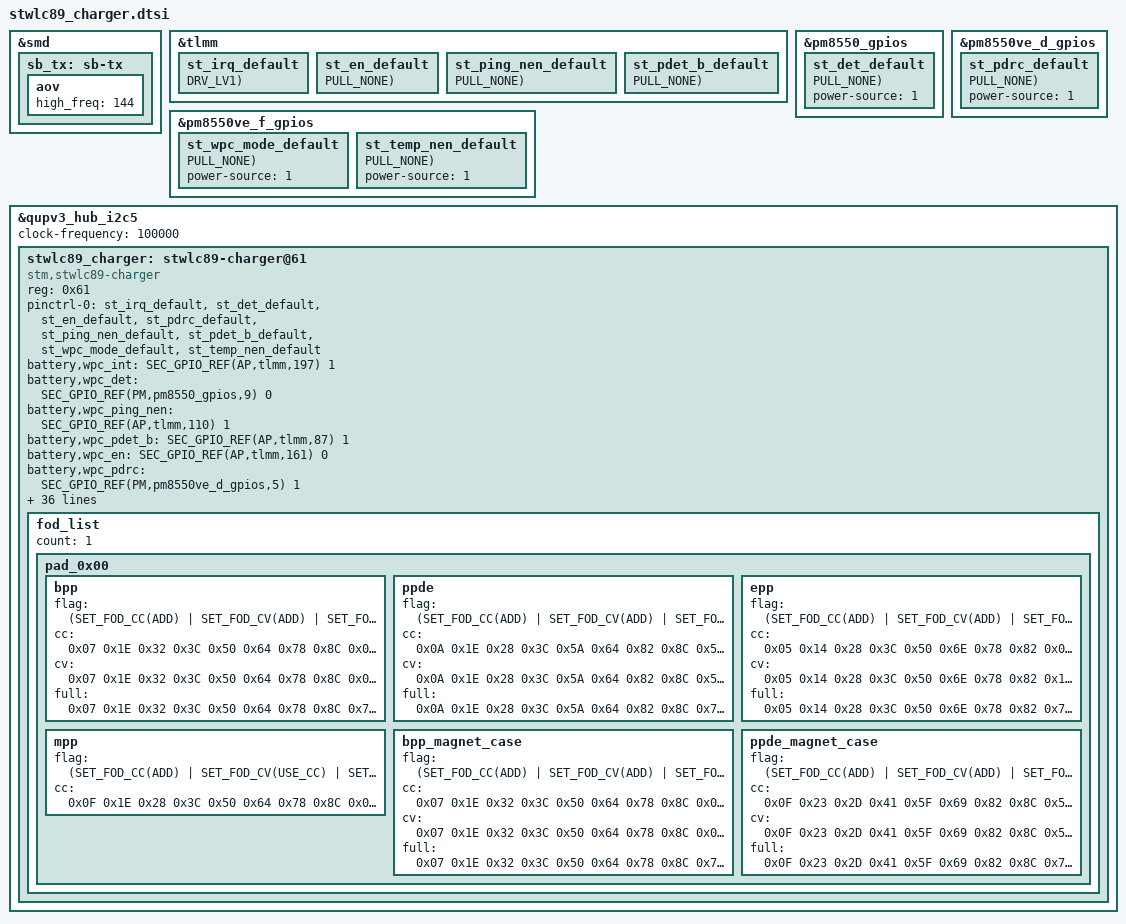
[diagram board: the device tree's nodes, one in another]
#include <dt-bindings/battery/sec-battery.h>

&smd {
	sb_tx: sb-tx {
	       aov {
		       high_freq = <144>;
	       };
       };
};

&tlmm {
	st_irq_default: st_irq_default {
		GPIO_CONFIG_PUD_DRV(AP,tlmm,197, FUNC_INPUT_WAKEUP, PULL_NONE, DRV_LV1);
	};
};

&pm8550_gpios {
	st_det_default: st_det_default {
		GPIO_CONFIG_PUD(PM,pm8550_gpios,9, FUNC_INPUT_WAKEUP, PULL_NONE);
	};
};

&tlmm {
	st_en_default: st_en_default {
		GPIO_CONFIG_PUD(AP,tlmm,161, FUNC_OUTPUT_LOW, PULL_NONE);
	};
};

#if 1
&pm8550ve_d_gpios {
	st_pdrc_default: st_pdrc_default {
		GPIO_CONFIG_PUD(PM,pm8550ve_d_gpios,5, FUNC_INPUT_WAKEUP, PULL_NONE);
	};
};
#endif

#if 1
&tlmm {
	st_ping_nen_default: st_ping_nen_default {
		GPIO_CONFIG_PUD(AP,tlmm,110, FUNC_OUTPUT_HIGH, PULL_NONE);
	};
};
#endif

#if 1
&tlmm {
	st_pdet_b_default: st_pdet_b_default {
		GPIO_CONFIG_PUD(AP,tlmm,87, FUNC_INPUT_WAKEUP, PULL_NONE);
	};
};
#endif

#if 0
&${mag_det_parent} {
	st_mag_det_default: st_mag_det_default {
		GPIO_CONFIG_PUD(${st_mag_det_gpio}, FUNC_OUTPUT_HIGH, PULL_NONE);
	};
};
#endif

#if 1
&pm8550ve_f_gpios {
	st_wpc_mode_default: st_wpc_mode_default {
		GPIO_CONFIG_PUD(PM,pm8550ve_f_gpios,8, FUNC_OUTPUT_HIGH, PULL_NONE);
	};
};
#endif

#if 1
&pm8550ve_f_gpios {
	st_temp_nen_default: st_temp_nen_default {
		GPIO_CONFIG_PUD(PM,pm8550ve_f_gpios,7, FUNC_OUTPUT_LOW, PULL_NONE);
	};
};
#endif

&qupv3_hub_i2c5 {
	#address-cells = <1>;
	#size-cells = <0>;
	status = "okay";
	clock-frequency = <100000>;

	stwlc89_charger: stwlc89-charger@61 {
		compatible = "stm,stwlc89-charger";
		reg = <0x61>;
		status = "okay";

		pinctrl-names = "default";
		pinctrl-0 = <&st_irq_default &st_det_default &st_en_default &st_pdrc_default
#if 1
			&st_ping_nen_default
#endif
#if 1
			&st_pdet_b_default
#endif
#if 0
			&st_mag_det_default
#endif
#if 1
			&st_wpc_mode_default
#endif
#if 1
			&st_temp_nen_default
#endif
			>;

		battery,wpc_int = <SEC_GPIO_REF(AP,tlmm,197) 1>; /* MFC_AP_INT */
		battery,wpc_det = <SEC_GPIO_REF(PM,pm8550_gpios,9) 0>; /* WPC_DET */
#if 0
		battery,mst_pwr_en = <SEC_GPIO_REF(${st_pwr_en_gpio}) 0>; /* MST_PWR_EN */
#endif
#if 1
		battery,wpc_ping_nen = <SEC_GPIO_REF(AP,tlmm,110) 1>; /* PING_NEN */
#endif
#if 1
		battery,wpc_pdet_b = <SEC_GPIO_REF(AP,tlmm,87) 1>; /* PDET_B */
#endif
		battery,wpc_en = <SEC_GPIO_REF(AP,tlmm,161) 0>; /* WPC_EN */
#if 1
		battery,wpc_pdrc = <SEC_GPIO_REF(PM,pm8550ve_d_gpios,5) 1>; /* VRECT_INT */
#endif
#if 0
		battery,wpc_mag_det = <SEC_GPIO_REF(${st_mag_det_gpio}) 0>; /* MAG_DET */
#endif
#if 1
		battery,wpc_mode = <SEC_GPIO_REF(PM,pm8550ve_f_gpios,8) 0>; /* WPC_MODE */
#endif
#if 1
		battery,temp_nen = <SEC_GPIO_REF(PM,pm8550ve_f_gpios,7) 0>; /* TEMP_nEN */
#endif
		battery,charger_name = "max77775-charger";
		battery,fuelgauge_name = "max77775-fuelgauge";
		battery,wireless_charger_name = "stwlc89-charger";
		battery,wc_cover_rpp = <0x44>;
		battery,phone_fod_threshold = <0x3b>;
		battery,wireless20_vout_list = <WIRELESS_VOUT_9V /* 0xA0 */
						WIRELESS_VOUT_12V /* 0xA1 */
						WIRELESS_VOUT_12V /* 0xA2 */
						WIRELESS_VOUT_12V /* 0xA3 */
						WIRELESS_VOUT_12V /* 0xA4 */
						WIRELESS_VOUT_12V>; /* 0xA5 */
		battery,wireless20_vrect_list = <MFC_AFC_CONF_12V_TX
						MFC_AFC_CONF_12_5V_TX
						MFC_AFC_CONF_12_5V_TX
						MFC_AFC_CONF_12_5V_TX
						MFC_AFC_CONF_12_5V_TX
						MFC_AFC_CONF_12_5V_TX>;
		battery,wireless20_max_power_list = <SEC_WIRELESS_RX_POWER_12W
						SEC_WIRELESS_RX_POWER_15W
						SEC_WIRELESS_RX_POWER_15W
						SEC_WIRELESS_RX_POWER_15W
						SEC_WIRELESS_RX_POWER_15W
						SEC_WIRELESS_RX_POWER_15W>;

		battery,buds_fod_ta_thresh = <0x0898>; /* 2200mW */
		battery,wpc_vout_ctrl_full = <WIRELESS_VOUT_5V_STEP>;
		battery,mis_align_guide;
		battery,mis_align_target_vout = <5000>;
		battery,epp_vout = <WIRELESS_VOUT_12V>;

		fod_list {
			count = <1>;

			pad_0x00 { /* DEFAULT PAD */
				bpp { /* DEFAULT OP MODE */
					flag = <(SET_FOD_CC(ADD) | SET_FOD_CV(ADD) | SET_FOD_FULL(ADD))>;
					cc = <0x05 0x06 0x07 0x1E 0x32 0x50 0x78 0x8C 0x09 0x0E
						0x0E 0x0E 0x0F 0x10 0x15 0x15 0x15 0x00 0x64 0x00>;
					cv = <0x05 0x06 0x07 0x1E 0x32 0x50 0x78 0x8C 0x12 0x17
						0x17 0x18 0x19 0x1E 0x1E 0x1E 0x1E 0x00 0x64 0x00>;
					full = <0x05 0x06 0x07 0x1E 0x32 0x50 0x78 0x8C 0x7F 0x7F
						0x7F 0x7F 0x7F 0x7F 0x7F 0x7F 0x7F 0x7F 0x7F 0x7F>;
				};

				ppde {
					flag = <(SET_FOD_CC(ADD) | SET_FOD_CV(ADD) | SET_FOD_FULL(ADD))>;
					cc = <0x0A 0x1E 0x32 0x46 0x5A 0x6E 0x82 0x96 0x1E 0x28
						0x50 0x50 0x14 0x23 0x28 0x2F 0x37 0x00 0x64 0x00>;
					cv = <0x0A 0x1E 0x32 0x46 0x5A 0x6E 0x82 0x96 0x27 0x31
						0x59 0x59 0x1D 0x2C 0x31 0x38 0x40 0x00 0x64 0x00>;
					full = <0x0A 0x1E 0x32 0x46 0x5A 0x6E 0x82 0x96 0x7F 0x7F
						0x7F 0x7F 0x7F 0x7F 0x7F 0x7F 0x7F 0x00 0x64 0x00>;
				};

				epp {
					flag = <(SET_FOD_CC(ADD) | SET_FOD_CV(ADD) | SET_FOD_FULL(ADD))>;
					cc = <0x07 0x08 0x09 0x1E 0x32 0x5A 0x87 0x8C 0x0B 0x17
						0x1F 0x28 0x23 0x32 0x3C 0x49 0x49 0x00 0x64 0x00>;
					cv = <0x07 0x08 0x09 0x1E 0x32 0x5A 0x87 0x8C 0x14 0x20
						0x28 0x31 0x2C 0x3B 0x45 0x52 0x52 0x00 0x64 0x00>;
					full = <0x07 0x08 0x09 0x1E 0x32 0x5A 0x87 0x8C 0x7F 0x7F
						0x7F 0x7F 0x7F 0x7F 0x7F 0x7F 0x7F 0x7F 0x7F 0x7F>;
				};

				mpp {
					flag = <(SET_FOD_CC(ADD) | SET_FOD_CV(USE_CC) | SET_FOD_FULL(USE_CC))>;
					cc = <0x14 0x1E 0x28 0x3C 0x50 0x64 0x78 0x8C 0x00 0x05
						0x07 0x0A 0x0C 0x10 0x14 0x19 0x23 0x00 0x32 0x00>;
				};
			};
		};
	};
};

/* /home/dpi/qb5_8814/workspace/P4_1716/android/kernel_platform/kmodule/battery/stable/paradigm/wireless/stwlc89/stwlc89_charger.pa3q.dtsi */
#include <dt-bindings/battery/sec-battery.h>

&st_pdrc_default {
	power-source = <1>; /* need to set default MV gpio to LV */
};

&st_det_default {
	power-source = <1>; /* need to set default MV gpio to LV */
};

#if 0
&st_mag_det_default {
	power-source = <1>; /* need to set default MV gpio to LV */
};
#endif

#if 1
&st_wpc_mode_default {
	power-source = <1>; /* need to set default MV gpio to LV */
};
#endif

#if 1
&st_temp_nen_default {
	power-source = <1>; /* need to set default MV gpio to LV */
};
#endif

&stwlc89_charger {
	battery,unknown_cmb_ctrl;
	battery,default_clamp_volt;
	battery,tx_max_op_freq = <1450>;
	battery,tx_min_op_freq = <1130>;
	battery,wireless20_iec_ploss_fod_enable = <0x1>;
	battery,tx_fod_gain = <0x72>;
	battery,buds_fod_thresh1 = <0x0DAC>;
	battery,buds_fod_ta_thresh = <0x0DAC>;
	battery,cep_timeout_xac = <900>;
	battery,epp_time_init = <100>;
	battery,epp_time_mid_1 = <100>;
	battery,epp_time_mid_2 = <1000>;
	battery,epp_time_final = <4000>;
	battery,fod_cnt_thresh = <10>;

	battery,opfreq_ctrl_pad_list = <
		0xF2 /* WC_PAD_N3300_L N3300 landscape mode */
		0x35 /* WC_PAD_N3300_P N3300 portrait mode */
		0xF1 /* WC_PAD_N5105_L N5105 landscape mode */
		0x34 /* WC_PAD_N5105_P N5105 portrait mode */
		0xA2 /* WC_PAD_N5200_L N5200 landscape mode */
		0xA1 /* WC_PAD_N5200_P N5200 portrait mode */
		>;

	battery,wireless20_vout_list = <WIRELESS_VOUT_10V /* 0xA0 */
					WIRELESS_VOUT_12V /* 0xA1 */
					WIRELESS_VOUT_12V /* 0xA2 */
					WIRELESS_VOUT_12V /* 0xA3 */
					WIRELESS_VOUT_12V /* 0xA4 */
					WIRELESS_VOUT_12V>; /* 0xA5 */
	battery,wireless20_vrect_list = <MFC_AFC_CONF_12V_TX
					MFC_AFC_CONF_12_5V_TX
					MFC_AFC_CONF_12_5V_TX
					MFC_AFC_CONF_12_5V_TX
					MFC_AFC_CONF_12_5V_TX
					MFC_AFC_CONF_12_5V_TX>;
	battery,wireless20_max_power_list = <SEC_WIRELESS_RX_POWER_11W
					SEC_WIRELESS_RX_POWER_15W
					SEC_WIRELESS_RX_POWER_15W
					SEC_WIRELESS_RX_POWER_15W
					SEC_WIRELESS_RX_POWER_15W
					SEC_WIRELESS_RX_POWER_15W>;
	fod_list {
		count = <1>;

		pad_0x00 { /* DEFAULT PAD */
			bpp { /* DEFAULT OP MODE */
				flag = <(SET_FOD_CC(ADD) | SET_FOD_CV(ADD) | SET_FOD_FULL(ADD))>;
				cc = <0x07 0x1E 0x32 0x3C 0x50 0x64 0x78 0x8C 0x06 0x06
					0x0D 0x12 0x14 0x17 0x19 0x19 0x19 0x00 0x55 0x00>;
				cv = <0x07 0x1E 0x32 0x3C 0x50 0x64 0x78 0x8C 0x0F 0x0F
					0x16 0x1B 0x1D 0x20 0x22 0x22 0x22 0x00 0x55 0x00>;
				full = <0x07 0x1E 0x32 0x3C 0x50 0x64 0x78 0x8C 0x7F 0x7F
					0x7F 0x7F 0x7F 0x7F 0x7F 0x7F 0x7F 0x00 0x55 0x00>;
			};

			bpp_magnet_case { /* DEFAULT OP MODE */
				flag = <(SET_FOD_CC(ADD) | SET_FOD_CV(ADD) | SET_FOD_FULL(ADD))>;
				cc = <0x07 0x1E 0x32 0x3C 0x50 0x64 0x78 0x8C 0x06 0x06
					0x0D 0x17 0x1B 0x1D 0x20 0x23 0x23 0x00 0x55 0x00>;
				cv = <0x07 0x1E 0x32 0x3C 0x50 0x64 0x78 0x8C 0x0F 0x0F
					0x16 0x20 0x24 0x26 0x29 0x2C 0x2C 0x00 0x55 0x00>;
				full = <0x07 0x1E 0x32 0x3C 0x50 0x64 0x78 0x8C 0x7F 0x7F
					0x7F 0x7F 0x7F 0x7F 0x7F 0x7F 0x7F 0x00 0x55 0x00>;
			};

			ppde {
				flag = <(SET_FOD_CC(ADD) | SET_FOD_CV(ADD) | SET_FOD_FULL(ADD))>;
				cc = <0x0A 0x1E 0x28 0x3C 0x5A 0x64 0x82 0x8C 0x50 0x50
						0x5A 0x64 0x69 0x69 0x78 0x7F 0x7F 0x00 0x64 0x00>;
				cv = <0x0A 0x1E 0x28 0x3C 0x5A 0x64 0x82 0x8C 0x5B 0x5B
						0x65 0x6F 0x74 0x74 0x7F 0x7F 0x7F 0x00 0x64 0x00>;
				full = <0x0A 0x1E 0x28 0x3C 0x5A 0x64 0x82 0x8C 0x7F 0x7F
						0x7F 0x7F 0x7F 0x7F 0x7F 0x7F 0x7F 0x00 0x64 0x00>;
			};

			ppde_magnet_case {
				flag = <(SET_FOD_CC(ADD) | SET_FOD_CV(ADD) | SET_FOD_FULL(ADD))>;
				cc = <0x0F 0x23 0x2D 0x41 0x5F 0x69 0x82 0x8C 0x54 0x54
					0x5E 0x68 0x69 0x69 0x78 0x7F 0x7F 0x32 0x64 0x00>;
				cv = <0x0F 0x23 0x2D 0x41 0x5F 0x69 0x82 0x8C 0x5F 0x5F
					0x69 0x73 0x74 0x74 0x7F 0x7F 0x7F 0x32 0x64 0x00>;
				full = <0x0F 0x23 0x2D 0x41 0x5F 0x69 0x82 0x8C 0x7F 0x7F
					0x7F 0x7F 0x7F 0x7F 0x7F 0x7F 0x7F 0x32 0x64 0x00>;
			};

			epp {
				flag = <(SET_FOD_CC(ADD) | SET_FOD_CV(ADD) | SET_FOD_FULL(ADD))>;
				cc = <0x05 0x14 0x28 0x3C 0x50 0x6E 0x78 0x82 0x0A 0x0F
					0x28 0x2D 0x7F 0x3C 0x41 0x49 0x49 0x00 0x55 0x00>;
				cv = <0x05 0x14 0x28 0x3C 0x50 0x6E 0x78 0x82 0x13 0x18
					0x31 0x36 0x7F 0x45 0x4A 0x52 0x52 0x00 0x55 0x00>;
				full = <0x05 0x14 0x28 0x3C 0x50 0x6E 0x78 0x82 0x7F 0x7F
					0x7F 0x7F 0x7F 0x7F 0x7F 0x7F 0x7F 0x00 0x55 0x00>;
			};

			mpp {
				flag = <(SET_FOD_CC(ADD) | SET_FOD_CV(USE_CC) | SET_FOD_FULL(USE_CC))>;
				cc = <0x0F 0x1E 0x28 0x3C 0x50 0x64 0x78 0x8C 0x00 0x00
						0x00 0x00 0x00 0x00 0x00 0x00 0x00 0x00 0xD4 0x00>;
			};
		};
	};
};
